AUTOSAR XML (schema 00049)
package /COM/VECTOR/CFG/WORKFLOW/SYSDESC/SYNC
  system SYSTEM: category=ECU_EXTRACT
    system mapping MAPPINGS
      data-mappings:
        data-element=COMPOSITIONTYPE.VcuRxMsg1_Sig0.VcuRxMsg1_Sig0, system-signal=VcuRxMsg1_Sig0
        data-element=COMPOSITIONTYPE.VcuRxMsg1_Sig2.VcuRxMsg1_Sig2, system-signal=VcuRxMsg1_Sig2
        data-element=COMPOSITIONTYPE.VcuRxMsg1_Sig1.VcuRxMsg1_Sig1, system-signal=VcuRxMsg1_Sig1
        data-element=COMPOSITIONTYPE.VcuRxMsg2_Sig3.VcuRxMsg2_Sig3, system-signal=VcuRxMsg2_Sig3
        data-element=COMPOSITIONTYPE.VcuRxMsg1_Sig3.VcuRxMsg1_Sig3, system-signal=VcuRxMsg1_Sig3
        data-element=COMPOSITIONTYPE.VcuRxMsg2_Sig0.VcuRxMsg2_Sig0, system-signal=VcuRxMsg2_Sig0
        data-element=COMPOSITIONTYPE.VcuRxMsg2_Sig2.VcuRxMsg2_Sig2, system-signal=VcuRxMsg2_Sig2
        data-element=COMPOSITIONTYPE.VcuRxMsg2_Sig1.VcuRxMsg2_Sig1, system-signal=VcuRxMsg2_Sig1
        data-element=COMPOSITIONTYPE.VcuTxMsg1_Sig1.VcuTxMsg1_Sig1, system-signal=VcuTxMsg1_Sig1
        data-element=COMPOSITIONTYPE.VcuTxMsg2_Sig1.VcuTxMsg2_Sig1, system-signal=VcuTxMsg2_Sig1
        data-element=COMPOSITIONTYPE.VcuTxMsg2_Sig2.VcuTxMsg2_Sig2, system-signal=VcuTxMsg2_Sig2
        data-element=COMPOSITIONTYPE.VcuTxMsg1_Sig3.VcuTxMsg1_Sig3, system-signal=VcuTxMsg1_Sig3
        data-element=COMPOSITIONTYPE.VcuTxMsg2_Sig0.VcuTxMsg2_Sig0, system-signal=VcuTxMsg2_Sig0
        data-element=COMPOSITIONTYPE.VcuTxMsg2_Sig3.VcuTxMsg2_Sig3, system-signal=VcuTxMsg2_Sig3
        data-element=COMPOSITIONTYPE.VcuTxMsg1_Sig2.VcuTxMsg1_Sig2, system-signal=VcuTxMsg1_Sig2
        data-element=COMPOSITIONTYPE.VcuTxMsg1_Sig0.VcuTxMsg1_Sig0, system-signal=VcuTxMsg1_Sig0
        data-element=COMPOSITIONTYPE.EXT1_Valid.EXT1_Valid, system-signal=EXT1_Valid
        data-element=COMPOSITIONTYPE.EXT3_Valid.EXT3_Valid, system-signal=EXT3_Valid
        data-element=COMPOSITIONTYPE.EXT_A_IN4.EXT_A_IN4, system-signal=EXT_A_IN4
        data-element=COMPOSITIONTYPE.EXT2_Valid.EXT2_Valid, system-signal=EXT2_Valid
        data-element=COMPOSITIONTYPE.EXT4_Valid.EXT4_Valid, system-signal=EXT4_Valid
        data-element=COMPOSITIONTYPE.EXT_A_IN{1..3}.EXT_A_IN{1..3}, system-signal=EXT_A_IN{1..3}
        data-element=COMPOSITIONTYPE.EXT10_Valid.EXT10_Valid, system-signal=EXT10_Valid
        data-element=COMPOSITIONTYPE.EXT12_Valid.EXT12_Valid, system-signal=EXT12_Valid
        data-element=COMPOSITIONTYPE.EXT15_Valid.EXT15_Valid, system-signal=EXT15_Valid
        data-element=COMPOSITIONTYPE.EXT5_Valid.EXT5_Valid, system-signal=EXT5_Valid
        data-element=COMPOSITIONTYPE.EXT_A_IN15.EXT_A_IN15, system-signal=EXT_A_IN15
        data-element=COMPOSITIONTYPE.EXT7_Valid.EXT7_Valid, system-signal=EXT7_Valid
        data-element=COMPOSITIONTYPE.EXT_A_IN13.EXT_A_IN13, system-signal=EXT_A_IN13
        data-element=COMPOSITIONTYPE.EXT_A_IN5.EXT_A_IN5, system-signal=EXT_A_IN5
        data-element=COMPOSITIONTYPE.EXT6_Valid.EXT6_Valid, system-signal=EXT6_Valid
        data-element=COMPOSITIONTYPE.EXT_A_IN12.EXT_A_IN12, system-signal=EXT_A_IN12
        data-element=COMPOSITIONTYPE.EXT_A_IN7.EXT_A_IN7, system-signal=EXT_A_IN7
        data-element=COMPOSITIONTYPE.EXT13_Valid.EXT13_Valid, system-signal=EXT13_Valid
        data-element=COMPOSITIONTYPE.EXT_A_IN9.EXT_A_IN9, system-signal=EXT_A_IN9
        data-element=COMPOSITIONTYPE.EXT9_Valid.EXT9_Valid, system-signal=EXT9_Valid
        data-element=COMPOSITIONTYPE.EXT8_Valid.EXT8_Valid, system-signal=EXT8_Valid
        data-element=COMPOSITIONTYPE.EXT11_Valid.EXT11_Valid, system-signal=EXT11_Valid
        data-element=COMPOSITIONTYPE.EXT_A_IN6.EXT_A_IN6, system-signal=EXT_A_IN6
        data-element=COMPOSITIONTYPE.EXT16_Valid.EXT16_Valid, system-signal=EXT16_Valid
        data-element=COMPOSITIONTYPE.EXT14_Valid.EXT14_Valid, system-signal=EXT14_Valid
        data-element=COMPOSITIONTYPE.EXT_A_IN16.EXT_A_IN16, system-signal=EXT_A_IN16
        data-element=COMPOSITIONTYPE.EXT_A_IN11.EXT_A_IN11, system-signal=EXT_A_IN11
        data-element=COMPOSITIONTYPE.EXT_A_IN8.EXT_A_IN8, system-signal=EXT_A_IN8
        data-element=COMPOSITIONTYPE.EXT_A_IN14.EXT_A_IN14, system-signal=EXT_A_IN14
        data-element=COMPOSITIONTYPE.EXT_A_IN10.EXT_A_IN10, system-signal=EXT_A_IN10
        data-element=COMPOSITIONTYPE.ECC_PMP2_SpdSet.ECC_PMP2_SpdSet, system-signal=ECC_PMP2_SpdSet
        data-element=COMPOSITIONTYPE.ECC_PMP3_SpdSet.ECC_PMP3_SpdSet, system-signal=ECC_PMP3_SpdSet
    root-software-compositions:
      root sw composition prototype COMPOSITIONTYPE: flat-map=FLATMAP, software-composition=COMPOSITIONTYPE
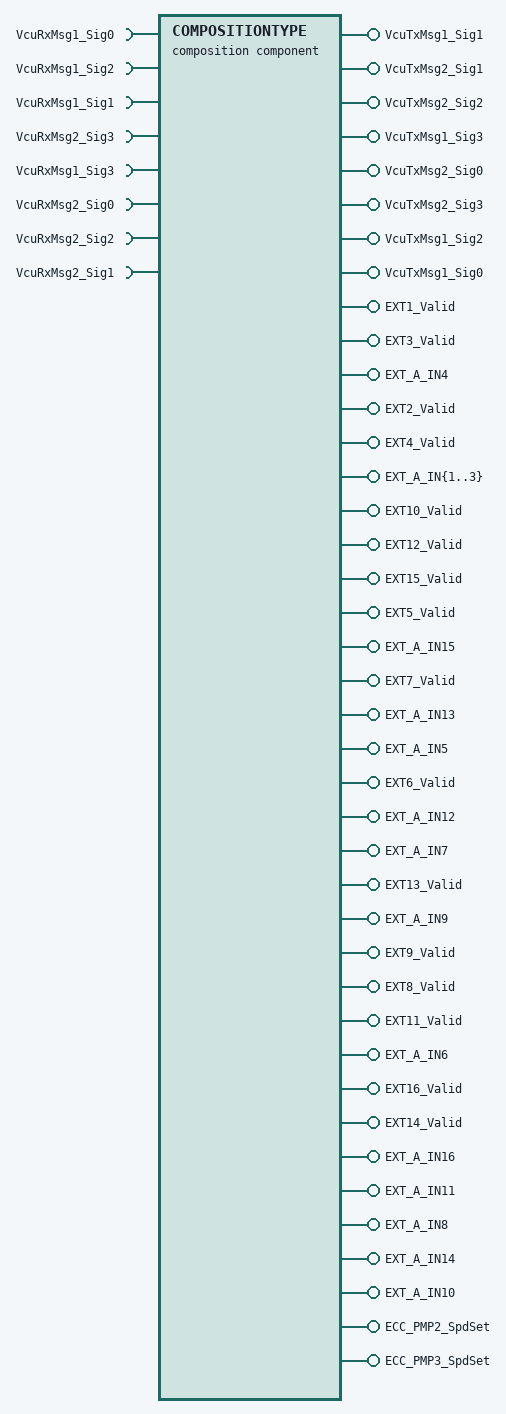
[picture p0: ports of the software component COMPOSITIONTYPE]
  composition sw component type COMPOSITIONTYPE  # UB:Derived from original system description
    8 x require port:
      VcuRxMsg1_Sig0: nonqueued-receiver-com-spec{data-element=VcuRxMsg1_Sig0, init-value=0}, required-interface=VcuRxMsg1_Sig0
      VcuRxMsg1_Sig2: nonqueued-receiver-com-spec{data-element=VcuRxMsg1_Sig2, init-value=0}, required-interface=VcuRxMsg1_Sig2
      VcuRxMsg1_Sig1: nonqueued-receiver-com-spec{data-element=VcuRxMsg1_Sig1, init-value=0}, required-interface=VcuRxMsg1_Sig1
      VcuRxMsg2_Sig3: nonqueued-receiver-com-spec{data-element=VcuRxMsg2_Sig3, init-value=0}, required-interface=VcuRxMsg2_Sig3
      VcuRxMsg1_Sig3: nonqueued-receiver-com-spec{data-element=VcuRxMsg1_Sig3, init-value=0}, required-interface=VcuRxMsg1_Sig3
      VcuRxMsg2_Sig0: nonqueued-receiver-com-spec{data-element=VcuRxMsg2_Sig0, init-value=0}, required-interface=VcuRxMsg2_Sig0
      VcuRxMsg2_Sig2: nonqueued-receiver-com-spec{data-element=VcuRxMsg2_Sig2, init-value=0}, required-interface=VcuRxMsg2_Sig2
      VcuRxMsg2_Sig1: nonqueued-receiver-com-spec{data-element=VcuRxMsg2_Sig1, init-value=0}, required-interface=VcuRxMsg2_Sig1
    42 x provide port:
      VcuTxMsg1_Sig1: nonqueued-sender-com-spec{data-element=VcuTxMsg1_Sig1, init-value=0}, provided-interface=VcuTxMsg1_Sig1
      VcuTxMsg2_Sig1: nonqueued-sender-com-spec{data-element=VcuTxMsg2_Sig1, init-value=0}, provided-interface=VcuTxMsg2_Sig1
      VcuTxMsg2_Sig2: nonqueued-sender-com-spec{data-element=VcuTxMsg2_Sig2, init-value=0}, provided-interface=VcuTxMsg2_Sig2
      VcuTxMsg1_Sig3: nonqueued-sender-com-spec{data-element=VcuTxMsg1_Sig3, init-value=0}, provided-interface=VcuTxMsg1_Sig3
      VcuTxMsg2_Sig0: nonqueued-sender-com-spec{data-element=VcuTxMsg2_Sig0, init-value=0}, provided-interface=VcuTxMsg2_Sig0
      VcuTxMsg2_Sig3: nonqueued-sender-com-spec{data-element=VcuTxMsg2_Sig3, init-value=0}, provided-interface=VcuTxMsg2_Sig3
      VcuTxMsg1_Sig2: nonqueued-sender-com-spec{data-element=VcuTxMsg1_Sig2, init-value=0}, provided-interface=VcuTxMsg1_Sig2
      VcuTxMsg1_Sig0: nonqueued-sender-com-spec{data-element=VcuTxMsg1_Sig0, init-value=0}, provided-interface=VcuTxMsg1_Sig0
      EXT1_Valid: nonqueued-sender-com-spec{data-element=EXT1_Valid, init-value=0}, provided-interface=EXT1_Valid
      EXT3_Valid: nonqueued-sender-com-spec{data-element=EXT3_Valid, init-value=0}, provided-interface=EXT3_Valid
      EXT_A_IN4: nonqueued-sender-com-spec{data-element=EXT_A_IN4, init-value=0}, provided-interface=EXT_A_IN4
      EXT2_Valid: nonqueued-sender-com-spec{data-element=EXT2_Valid, init-value=0}, provided-interface=EXT2_Valid
      EXT4_Valid: nonqueued-sender-com-spec{data-element=EXT4_Valid, init-value=0}, provided-interface=EXT4_Valid
      EXT_A_IN{1..3}: nonqueued-sender-com-spec{data-element=EXT_A_IN{1..3}, init-value=0}, provided-interface=EXT_A_IN{1..3}
      EXT10_Valid: nonqueued-sender-com-spec{data-element=EXT10_Valid, init-value=0}, provided-interface=EXT10_Valid
      EXT12_Valid: nonqueued-sender-com-spec{data-element=EXT12_Valid, init-value=0}, provided-interface=EXT12_Valid
      EXT15_Valid: nonqueued-sender-com-spec{data-element=EXT15_Valid, init-value=0}, provided-interface=EXT15_Valid
      EXT5_Valid: nonqueued-sender-com-spec{data-element=EXT5_Valid, init-value=0}, provided-interface=EXT5_Valid
      EXT_A_IN15: nonqueued-sender-com-spec{data-element=EXT_A_IN15, init-value=0}, provided-interface=EXT_A_IN15
      EXT7_Valid: nonqueued-sender-com-spec{data-element=EXT7_Valid, init-value=0}, provided-interface=EXT7_Valid
      EXT_A_IN13: nonqueued-sender-com-spec{data-element=EXT_A_IN13, init-value=0}, provided-interface=EXT_A_IN13
      EXT_A_IN5: nonqueued-sender-com-spec{data-element=EXT_A_IN5, init-value=0}, provided-interface=EXT_A_IN5
      EXT6_Valid: nonqueued-sender-com-spec{data-element=EXT6_Valid, init-value=0}, provided-interface=EXT6_Valid
      EXT_A_IN12: nonqueued-sender-com-spec{data-element=EXT_A_IN12, init-value=0}, provided-interface=EXT_A_IN12
      EXT_A_IN7: nonqueued-sender-com-spec{data-element=EXT_A_IN7, init-value=0}, provided-interface=EXT_A_IN7
      EXT13_Valid: nonqueued-sender-com-spec{data-element=EXT13_Valid, init-value=0}, provided-interface=EXT13_Valid
      EXT_A_IN9: nonqueued-sender-com-spec{data-element=EXT_A_IN9, init-value=0}, provided-interface=EXT_A_IN9
      EXT9_Valid: nonqueued-sender-com-spec{data-element=EXT9_Valid, init-value=0}, provided-interface=EXT9_Valid
      EXT8_Valid: nonqueued-sender-com-spec{data-element=EXT8_Valid, init-value=0}, provided-interface=EXT8_Valid
      EXT11_Valid: nonqueued-sender-com-spec{data-element=EXT11_Valid, init-value=0}, provided-interface=EXT11_Valid
      EXT_A_IN6: nonqueued-sender-com-spec{data-element=EXT_A_IN6, init-value=0}, provided-interface=EXT_A_IN6
      EXT16_Valid: nonqueued-sender-com-spec{data-element=EXT16_Valid, init-value=0}, provided-interface=EXT16_Valid
      EXT14_Valid: nonqueued-sender-com-spec{data-element=EXT14_Valid, init-value=0}, provided-interface=EXT14_Valid
      EXT_A_IN16: nonqueued-sender-com-spec{data-element=EXT_A_IN16, init-value=0}, provided-interface=EXT_A_IN16
      EXT_A_IN11: nonqueued-sender-com-spec{data-element=EXT_A_IN11, init-value=0}, provided-interface=EXT_A_IN11
      EXT_A_IN8: nonqueued-sender-com-spec{data-element=EXT_A_IN8, init-value=0}, provided-interface=EXT_A_IN8
      EXT_A_IN14: nonqueued-sender-com-spec{data-element=EXT_A_IN14, init-value=0}, provided-interface=EXT_A_IN14
      EXT_A_IN10: nonqueued-sender-com-spec{data-element=EXT_A_IN10, init-value=0}, provided-interface=EXT_A_IN10
      ECC_PMP2_SpdSet: nonqueued-sender-com-spec{data-element=ECC_PMP2_SpdSet, init-value=0}, provided-interface=ECC_PMP2_SpdSet
      ECC_PMP3_SpdSet: nonqueued-sender-com-spec{data-element=ECC_PMP3_SpdSet, init-value=0}, provided-interface=ECC_PMP3_SpdSet
    19 x component:
      BswM: type=BswM
      EcuM: type=EcuM
      Os_OsCore0_swc: type=Os_OsCore0_swc
      SWC1: type=SWC1
      ComM: type=ComM
      Det: type=Det
      PowerMng_SWC: type=PowerMng_SWC
      Com_SWC: type=Com_SWC
      NvM: type=NvM
      NvM_SWC: type=NvM_SWC
      DemMaster_0: type=DemMaster_0
      DemSatellite_0: type=DemSatellite_0
      Dcm: type=Dcm
      DIAG_SWC: type=DIAG_SWC
      IoHwAb_SWC: type=IoHwAb_SWC
      Os_OsCore1_swc: type=Os_OsCore1_swc
      Os_OsCore2_swc: type=Os_OsCore2_swc
      Core2App_SWC: type=Core2App_SWC
      Core1App_SWC: type=Core1App_SWC
    connect BswM.Switch_ESH_ModeSwitch -> BswM.Notification_ESH_ModeNotification
    connect SWC1.Request_ESH_RunRequest_0 -> BswM.Request_ESH_RunRequest_0
    connect ComM.UR_CN_TC37X_VCU_CAN00_b1b4f272 -> SWC1.UR_CN_TC37X_VCU_CAN00_b1b4f272
    delegate Com_SWC.VcuRxMsg1_Sig0 <-> outer port VcuRxMsg1_Sig0  # UB:Derived from original system description
    delegate Com_SWC.VcuRxMsg1_Sig2 <-> outer port VcuRxMsg1_Sig2  # UB:Derived from original system description
    delegate Com_SWC.VcuRxMsg1_Sig1 <-> outer port VcuRxMsg1_Sig1  # UB:Derived from original system description
    delegate Com_SWC.VcuRxMsg2_Sig3 <-> outer port VcuRxMsg2_Sig3  # UB:Derived from original system description
    delegate Com_SWC.VcuRxMsg1_Sig3 <-> outer port VcuRxMsg1_Sig3  # UB:Derived from original system description
    delegate Com_SWC.VcuRxMsg2_Sig0 <-> outer port VcuRxMsg2_Sig0  # UB:Derived from original system description
    delegate Com_SWC.VcuRxMsg2_Sig2 <-> outer port VcuRxMsg2_Sig2  # UB:Derived from original system description
    delegate Com_SWC.VcuRxMsg2_Sig1 <-> outer port VcuRxMsg2_Sig1  # UB:Derived from original system description
    delegate Com_SWC.VcuTxMsg1_Sig1 <-> outer port VcuTxMsg1_Sig1  # UB:Derived from original system description
    delegate Com_SWC.VcuTxMsg2_Sig1 <-> outer port VcuTxMsg2_Sig1  # UB:Derived from original system description
    delegate Com_SWC.VcuTxMsg2_Sig2 <-> outer port VcuTxMsg2_Sig2  # UB:Derived from original system description
    delegate Com_SWC.VcuTxMsg1_Sig3 <-> outer port VcuTxMsg1_Sig3  # UB:Derived from original system description
    delegate Com_SWC.VcuTxMsg2_Sig0 <-> outer port VcuTxMsg2_Sig0  # UB:Derived from original system description
    delegate Com_SWC.VcuTxMsg2_Sig3 <-> outer port VcuTxMsg2_Sig3  # UB:Derived from original system description
    delegate Com_SWC.VcuTxMsg1_Sig2 <-> outer port VcuTxMsg1_Sig2  # UB:Derived from original system description
    delegate Com_SWC.VcuTxMsg1_Sig0 <-> outer port VcuTxMsg1_Sig0  # UB:Derived from original system description
    connect SWC1.NvM_Data_IF_UserData1_Send -> NvM_SWC.NvM_Data_IF_UserData1_Recv  # UB:Derived from original system description
    connect NvM_SWC.NvM_Data_IF_UserData1_Send -> SWC1.NvM_Data_IF_UserData1_Recv  # UB:Derived from original system description
    connect SWC1.NvSWC_NvMNotifyJobFinished_UserData1 -> NvM_SWC.NvSWC_NvMNotifyJobFinished_NVBlockDescriptor_UserData1  # UB:Derived from original system description
    connect SWC1.NvM_Data_IF_UserData2_Send -> NvM_SWC.NvM_Data_IF_UserData2_Rcev  # UB:Derived from original system description
    connect NvM_SWC.NvM_Data_IF_UserData2_Send -> SWC1.NvM_Data_IF_UserData2_Recv  # UB:Derived from original system description
    connect SWC1.NvSWC_NvMNotifyJobFinished_UserData2 -> NvM_SWC.NvSWC_NvMNotifyJobFinished_NVBlockDescriptor_UserData2  # UB:Derived from original system description
    connect NvM.PS_SWC1NvBlockNeed_UserData3 -> SWC1.NvMService_AC3_SRBS_NvBlockNeed_UserData3
    connect NvM_SWC.NvMService_NVBlockDescriptor_UserData2 -> SWC1.NvSWC_UserData2_NvMService_AC3_SRBS  # UB:Derived from original system description
    connect DIAG_SWC.DataServices_VCU_DID_00_DataRecord -> Dcm.DataServices_VCU_DID_00_DataRecord
    connect NvM.PS_DIAG_SWC_NvBlockNeed_DiagDID_00 -> DIAG_SWC.PS_DIAG_SWC_NvBlockNeed_DiagDID_00
    connect DIAG_SWC.RoutineServices_Vcu_Roution_00 -> Dcm.RoutineServices_Vcu_Roution_00
    connect ComM.UR_CN_TC37X_VCU_CAN01_5e76994c -> SWC1.UR_CN_TC37X_VCU_CAN01_5e76994c
    delegate Com_SWC.EXT1_Valid <-> outer port EXT1_Valid  # UB:Derived from original system description
    delegate Com_SWC.EXT3_Valid <-> outer port EXT3_Valid  # UB:Derived from original system description
    delegate Com_SWC.EXT_A_IN4 <-> outer port EXT_A_IN4  # UB:Derived from original system description
    delegate Com_SWC.EXT2_Valid <-> outer port EXT2_Valid  # UB:Derived from original system description
    delegate Com_SWC.EXT4_Valid <-> outer port EXT4_Valid  # UB:Derived from original system description
    delegate Com_SWC.EXT_A_IN{1..3} <-> outer port EXT_A_IN{1..3}  # UB:Derived from original system description
    delegate Com_SWC.EXT10_Valid <-> outer port EXT10_Valid  # UB:Derived from original system description
    delegate Com_SWC.EXT12_Valid <-> outer port EXT12_Valid  # UB:Derived from original system description
    delegate Com_SWC.EXT15_Valid <-> outer port EXT15_Valid  # UB:Derived from original system description
    delegate Com_SWC.EXT5_Valid <-> outer port EXT5_Valid  # UB:Derived from original system description
    delegate Com_SWC.EXT_A_IN15 <-> outer port EXT_A_IN15  # UB:Derived from original system description
    delegate Com_SWC.EXT7_Valid <-> outer port EXT7_Valid  # UB:Derived from original system description
    delegate Com_SWC.EXT_A_IN13 <-> outer port EXT_A_IN13  # UB:Derived from original system description
    delegate Com_SWC.EXT_A_IN5 <-> outer port EXT_A_IN5  # UB:Derived from original system description
    delegate Com_SWC.EXT6_Valid <-> outer port EXT6_Valid  # UB:Derived from original system description
    delegate Com_SWC.EXT_A_IN12 <-> outer port EXT_A_IN12  # UB:Derived from original system description
    delegate Com_SWC.EXT_A_IN7 <-> outer port EXT_A_IN7  # UB:Derived from original system description
    delegate Com_SWC.EXT13_Valid <-> outer port EXT13_Valid  # UB:Derived from original system description
    delegate Com_SWC.EXT_A_IN9 <-> outer port EXT_A_IN9  # UB:Derived from original system description
    delegate Com_SWC.EXT9_Valid <-> outer port EXT9_Valid  # UB:Derived from original system description
    delegate Com_SWC.EXT8_Valid <-> outer port EXT8_Valid  # UB:Derived from original system description
    delegate Com_SWC.EXT11_Valid <-> outer port EXT11_Valid  # UB:Derived from original system description
    delegate Com_SWC.EXT_A_IN6 <-> outer port EXT_A_IN6  # UB:Derived from original system description
    delegate Com_SWC.EXT16_Valid <-> outer port EXT16_Valid  # UB:Derived from original system description
    delegate Com_SWC.EXT14_Valid <-> outer port EXT14_Valid  # UB:Derived from original system description
    delegate Com_SWC.EXT_A_IN16 <-> outer port EXT_A_IN16  # UB:Derived from original system description
    delegate Com_SWC.EXT_A_IN11 <-> outer port EXT_A_IN11  # UB:Derived from original system description
    delegate Com_SWC.EXT_A_IN8 <-> outer port EXT_A_IN8  # UB:Derived from original system description
    delegate Com_SWC.EXT_A_IN14 <-> outer port EXT_A_IN14  # UB:Derived from original system description
    delegate Com_SWC.EXT_A_IN10 <-> outer port EXT_A_IN10  # UB:Derived from original system description
    connect ComM.UR_CN_KAMA_FP_EPT_0303_b67fd6a6 -> SWC1.UR_CN_KAMA_FP_EPT_0303_b67fd6a6
    connect ComM.UR_CN_LIN00_984dfd9e -> SWC1.UR_CN_LIN00_984dfd9e
    connect DemMaster_0.OpCycle_PowerCycle -> DIAG_SWC.OpCycle_PowerCycle
    delegate Com_SWC.ECC_PMP2_SpdSet <-> outer port ECC_PMP2_SpdSet  # UB:Derived from original system description
    delegate Com_SWC.ECC_PMP3_SpdSet <-> outer port ECC_PMP3_SpdSet  # UB:Derived from original system description
    connect DIAG_SWC.SecurityAccess_Level_3 -> Dcm.SecurityAccess_Level_3
    connect NvM.PS_DIAG_SWC_NvBlockNeed_AttemptCounter -> DIAG_SWC.NvMService_AC3_SRBS_NvBlockNeed_AttemptCounter
    connect DemSatellite_0.Event_DTC_0X000002 -> DIAG_SWC.Event_DTC_0x000002
    connect DemSatellite_0.Event_DTC_0X000003 -> DIAG_SWC.Event_DTC_0x000003
    connect DIAG_SWC.CBReadData_DID_0xf1a{0..3}_F1A{0..3}_Data -> DemMaster_0.CBReadData_DID_0xf1a{0..3}_F1A{0..3}_Data
    connect ComM.UR_CN_TC37X_VCU_CAN03_5a834971 -> SWC1.UR_CN_TC37X_VCU_CAN03_5a834971
    connect DemSatellite_0.EvtInfo_CAN01_ComLost -> DIAG_SWC.EvtInfo_CAN01_ComLost
    connect DemSatellite_0.Event_CAN01_ComLost -> DIAG_SWC.Event_CAN01_ComLost
    connect DemMaster_0.OpCycle_IgnitionCycle -> DIAG_SWC.OpCycle_IgnitionCycle
    connect DemMaster_0.EnableCond_KL15_High -> DIAG_SWC.EnableCond_KL15_High
    connect NvM.PS_DIAG_SWC_NvBlockNeed_DID_F193 -> DIAG_SWC.PS_DIAG_SWC_NvBlockNeed_DID_F193
    connect DIAG_SWC.DataServices_Hardware_Version_Hardware_Version_Number -> Dcm.DataServices_Hardware_Version_Hardware_Version_Number
    connect IoHwAb_SWC.P_Arry8Bytes -> Core1App_SWC.P_Arry8Bytes  # UB:Derived from original system description
  end to end protection set E2EPROTECTIONSET
  port interface mapping set PORTINTERFACEMAPPINGSET
